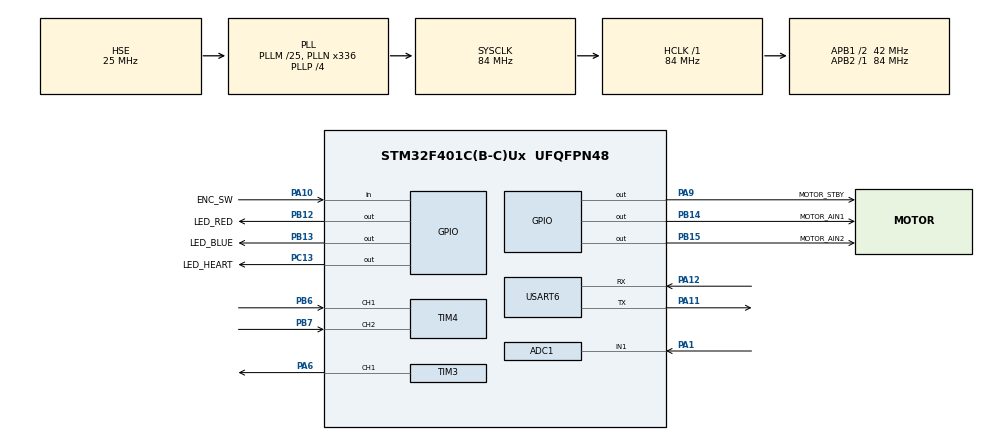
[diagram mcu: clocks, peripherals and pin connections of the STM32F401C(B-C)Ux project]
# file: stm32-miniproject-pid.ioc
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ADC1.Channel-1\#ChannelRegularConversion=ADC_CHANNEL_1
ADC1.NbrOfConversionFlag=1
ADC1.Rank-1\#ChannelRegularConversion=1
ADC1.SamplingTime-1\#ChannelRegularConversion=ADC_SAMPLETIME_84CYCLES
ADC1.master=1
Dma.Request0=USART6_TX
Dma.USART6_TX.0.Direction=DMA_MEMORY_TO_PERIPH
Dma.USART6_TX.0.FIFOMode=DMA_FIFOMODE_DISABLE
Dma.USART6_TX.0.Instance=DMA2_Stream6
Dma.USART6_TX.0.MemDataAlignment=DMA_MDATAALIGN_BYTE
Dma.USART6_TX.0.MemInc=DMA_MINC_ENABLE
Dma.USART6_TX.0.Mode=DMA_NORMAL
Dma.USART6_TX.0.PeriphDataAlignment=DMA_PDATAALIGN_BYTE
Dma.USART6_TX.0.PeriphInc=DMA_PINC_DISABLE
Dma.USART6_TX.0.Priority=DMA_PRIORITY_LOW
FREERTOS.Tasks01=defaultTask,24,128,StartDefaultTask,Default,NULL,Dynamic,NULL,NULL
FREERTOS.configCHECK_FOR_STACK_OVERFLOW=2
FREERTOS.configTOTAL_HEAP_SIZE=4096
FREERTOS.configUSE_NEWLIB_REENTRANT=1
Mcu.Family=STM32F4
Mcu.Name=STM32F401C(B-C)Ux
Mcu.Package=UFQFPN48
NVIC.DMA2_Stream6_IRQn=true\:5\:0\:false\:false\:true\:true\:false\:true\:true
NVIC.PriorityGroup=NVIC_PRIORITYGROUP_4
NVIC.TIM1_UP_TIM10_IRQn=true\:15\:0\:false\:false\:true\:false\:false\:true\:true
NVIC.TimeBase=TIM1_UP_TIM10_IRQn
NVIC.TimeBaseIP=TIM1
PA1.Signal=ADCx_IN1
PA10.GPIO_Label=ENC_SW
PA10.GPIO_PuPd=GPIO_PULLUP
PA10.Signal=GPIO_Input
PA11.Mode=Asynchronous
PA11.Signal=USART6_TX
PA12.Mode=Asynchronous
PA12.Signal=USART6_RX
PA13.Mode=Serial_Wire
PA13.Signal=SYS_JTMS-SWDIO
PA14.Mode=Serial_Wire
PA14.Signal=SYS_JTCK-SWCLK
PA6.Signal=S_TIM3_CH1
PA9.GPIO_Label=MOTOR_STBY
PA9.Signal=GPIO_Output
PB12.GPIO_Label=LED_RED
PB12.Signal=GPIO_Output
PB13.GPIO_Label=LED_BLUE
PB13.Signal=GPIO_Output
PB14.GPIO_Label=MOTOR_AIN1
PB14.PinState=GPIO_PIN_RESET
PB14.Signal=GPIO_Output
PB15.GPIO_Label=MOTOR_AIN2
PB15.PinState=GPIO_PIN_RESET
PB15.Signal=GPIO_Output
PB6.Signal=S_TIM4_CH1
PB7.Signal=S_TIM4_CH2
PC13-ANTI_TAMP.GPIO_Label=LED_HEART
PC13-ANTI_TAMP.PinState=GPIO_PIN_SET
PC13-ANTI_TAMP.Signal=GPIO_Output
PH0\ -\ OSC_IN.Mode=HSE-External-Oscillator
PH0\ -\ OSC_IN.Signal=RCC_OSC_IN
PH1\ -\ OSC_OUT.Mode=HSE-External-Oscillator
PH1\ -\ OSC_OUT.Signal=RCC_OSC_OUT
ProjectManager.HeapSize=0x200
ProjectManager.StackSize=0x400
ProjectManager.TargetToolchain=STM32CubeIDE
RCC.48MHZClocksFreq_Value=84000000
RCC.AHBFreq_Value=84000000
RCC.APB1CLKDivider=RCC_HCLK_DIV2
RCC.APB1Freq_Value=42000000
RCC.APB1TimFreq_Value=84000000
RCC.APB2Freq_Value=84000000
RCC.APB2TimFreq_Value=84000000
RCC.CortexFreq_Value=84000000
RCC.HCLKFreq_Value=84000000
RCC.HSE_VALUE=25000000
RCC.HSI_VALUE=16000000
RCC.LSE_VALUE=32768
RCC.PLLM=25
RCC.PLLN=336
RCC.PLLP=RCC_PLLP_DIV4
RCC.PLLSourceVirtual=RCC_PLLSOURCE_HSE
RCC.SYSCLKFreq_VALUE=84000000
RCC.SYSCLKSource=RCC_SYSCLKSOURCE_PLLCLK
RCC.VCOOutputFreq_Value=336000000
SH.ADCx_IN1.0=ADC1_IN1,IN1
SH.S_TIM3_CH1.0=TIM3_CH1,PWM Generation1 CH1
SH.S_TIM4_CH1.0=TIM4_CH1,Encoder_Interface
SH.S_TIM4_CH2.0=TIM4_CH2,Encoder_Interface
TIM3.AutoReloadPreload=TIM_AUTORELOAD_PRELOAD_ENABLE
TIM3.Channel-PWM\ Generation1\ CH1=TIM_CHANNEL_1
TIM3.Period=4199
TIM4.EncoderMode=TIM_ENCODERMODE_TI12
TIM4.IC1Filter=10
TIM4.IC2Filter=10
USART6.VirtualMode=VM_ASYNC
VP_FREERTOS_VS_CMSIS_V2.Mode=CMSIS_V2
VP_SYS_VS_tim1.Mode=TIM1
VP_TIM3_VS_ClockSourceINT.Mode=Internal
board=custom

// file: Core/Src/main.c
/* USER CODE BEGIN Header */
/**
  ******************************************************************************
  * @file           : main.c
  * @brief          : Main program body
  ******************************************************************************
  * @attention
  *
  * Copyright (c) 2026 STMicroelectronics.
  * All rights reserved.
  *
  * This software is licensed under terms that can be found in the LICENSE file
  * in the root directory of this software component.
  * If no LICENSE file comes with this software, it is provided AS-IS.
  *
  ******************************************************************************
  */
/* USER CODE END Header */
#include "main.h"
#include "cmsis_os.h"

/* USER CODE BEGIN Includes */
#include "app_main.h"
#include <stdio.h>
/* USER CODE END Includes */

ADC_HandleTypeDef hadc1;

TIM_HandleTypeDef htim3;
TIM_HandleTypeDef htim4;

UART_HandleTypeDef huart6;
DMA_HandleTypeDef hdma_usart6_tx;

/* Definitions for defaultTask */
osThreadId_t defaultTaskHandle;
const osThreadAttr_t defaultTask_attributes = {
  .name = "defaultTask",
  .stack_size = 128 * 4,
  .priority = (osPriority_t) osPriorityNormal,
};

void SystemClock_Config(void);
static void MX_GPIO_Init(void);
static void MX_DMA_Init(void);
static void MX_ADC1_Init(void);
static void MX_TIM3_Init(void);
static void MX_TIM4_Init(void);
static void MX_USART6_UART_Init(void);
void StartDefaultTask(void *argument);

/* USER CODE BEGIN 0 */
//int __io_putchar(int ch) {
//    HAL_UART_Transmit(&huart1, (uint8_t *)&ch, 1, 0xFFFF);
//    return ch;
//}
/* USER CODE END 0 */

int main(void)
{

  /* MCU Configuration--------------------------------------------------------*/

  /* Reset of all peripherals, Initializes the Flash interface and the Systick. */
  HAL_Init();

  /* Configure the system clock */
  SystemClock_Config();

  /* Initialize all configured peripherals */
  MX_GPIO_Init();
  MX_DMA_Init();
  MX_ADC1_Init();
  MX_TIM3_Init();
  MX_TIM4_Init();
  MX_USART6_UART_Init();
  /* USER CODE BEGIN 2 */
  app_init();
  /* USER CODE END 2 */

  /* Init scheduler */
  osKernelInitialize();

  /* Create the thread(s) */
  /* creation of defaultTask */
  defaultTaskHandle = osThreadNew(StartDefaultTask, NULL, &defaultTask_attributes);

  /* USER CODE BEGIN RTOS_THREADS */

  // delete generated task from CubeMX
  if (defaultTaskHandle != NULL) {
     osThreadTerminate(defaultTaskHandle);
     defaultTaskHandle = NULL;
  }

  app_start();

  /* USER CODE END RTOS_THREADS */

  /* Start scheduler */
  osKernelStart();

  /* We should never get here as control is now taken by the scheduler */

  /* Infinite loop */
  while (1)
  {

  }
}

void SystemClock_Config(void)
{
  RCC_OscInitTypeDef RCC_OscInitStruct = {0};
  RCC_ClkInitTypeDef RCC_ClkInitStruct = {0};

  /** Configure the main internal regulator output voltage
  */
  __HAL_RCC_PWR_CLK_ENABLE();
  __HAL_PWR_VOLTAGESCALING_CONFIG(PWR_REGULATOR_VOLTAGE_SCALE2);

  /** Initializes the RCC Oscillators according to the specified parameters
  * in the RCC_OscInitTypeDef structure.
  */
  RCC_OscInitStruct.OscillatorType = RCC_OSCILLATORTYPE_HSE;
  RCC_OscInitStruct.HSEState = RCC_HSE_ON;
  RCC_OscInitStruct.PLL.PLLState = RCC_PLL_ON;
  RCC_OscInitStruct.PLL.PLLSource = RCC_PLLSOURCE_HSE;
  RCC_OscInitStruct.PLL.PLLM = 25;
  RCC_OscInitStruct.PLL.PLLN = 336;
  RCC_OscInitStruct.PLL.PLLP = RCC_PLLP_DIV4;
  RCC_OscInitStruct.PLL.PLLQ = 4;
  if (HAL_RCC_OscConfig(&RCC_OscInitStruct) != HAL_OK)
  {
    Error_Handler();
  }

  /** Initializes the CPU, AHB and APB buses clocks
  */
  RCC_ClkInitStruct.ClockType = RCC_CLOCKTYPE_HCLK|RCC_CLOCKTYPE_SYSCLK
                              |RCC_CLOCKTYPE_PCLK1|RCC_CLOCKTYPE_PCLK2;
  RCC_ClkInitStruct.SYSCLKSource = RCC_SYSCLKSOURCE_PLLCLK;
  RCC_ClkInitStruct.AHBCLKDivider = RCC_SYSCLK_DIV1;
  RCC_ClkInitStruct.APB1CLKDivider = RCC_HCLK_DIV2;
  RCC_ClkInitStruct.APB2CLKDivider = RCC_HCLK_DIV1;

  if (HAL_RCC_ClockConfig(&RCC_ClkInitStruct, FLASH_LATENCY_2) != HAL_OK)
  {
    Error_Handler();
  }
}

static void MX_ADC1_Init(void)
{

  ADC_ChannelConfTypeDef sConfig = {0};

  /** Configure the global features of the ADC (Clock, Resolution, Data Alignment and number of conversion)
  */
  hadc1.Instance = ADC1;
  hadc1.Init.ClockPrescaler = ADC_CLOCK_SYNC_PCLK_DIV4;
  hadc1.Init.Resolution = ADC_RESOLUTION_12B;
  hadc1.Init.ScanConvMode = DISABLE;
  hadc1.Init.ContinuousConvMode = DISABLE;
  hadc1.Init.DiscontinuousConvMode = DISABLE;
  hadc1.Init.ExternalTrigConvEdge = ADC_EXTERNALTRIGCONVEDGE_NONE;
  hadc1.Init.ExternalTrigConv = ADC_SOFTWARE_START;
  hadc1.Init.DataAlign = ADC_DATAALIGN_RIGHT;
  hadc1.Init.NbrOfConversion = 1;
  hadc1.Init.DMAContinuousRequests = DISABLE;
  hadc1.Init.EOCSelection = ADC_EOC_SINGLE_CONV;
  if (HAL_ADC_Init(&hadc1) != HAL_OK)
  {
    Error_Handler();
  }

  /** Configure for the selected ADC regular channel its corresponding rank in the sequencer and its sample time.
  */
  sConfig.Channel = ADC_CHANNEL_1;
  sConfig.Rank = 1;
  sConfig.SamplingTime = ADC_SAMPLETIME_84CYCLES;
  if (HAL_ADC_ConfigChannel(&hadc1, &sConfig) != HAL_OK)
  {
    Error_Handler();
  }

}

static void MX_TIM3_Init(void)
{

  TIM_ClockConfigTypeDef sClockSourceConfig = {0};
  TIM_MasterConfigTypeDef sMasterConfig = {0};
  TIM_OC_InitTypeDef sConfigOC = {0};

  htim3.Instance = TIM3;
  htim3.Init.Prescaler = 0;
  htim3.Init.CounterMode = TIM_COUNTERMODE_UP;
  htim3.Init.Period = 4199;
  htim3.Init.ClockDivision = TIM_CLOCKDIVISION_DIV1;
  htim3.Init.AutoReloadPreload = TIM_AUTORELOAD_PRELOAD_ENABLE;
  if (HAL_TIM_Base_Init(&htim3) != HAL_OK)
  {
    Error_Handler();
  }
  sClockSourceConfig.ClockSource = TIM_CLOCKSOURCE_INTERNAL;
  if (HAL_TIM_ConfigClockSource(&htim3, &sClockSourceConfig) != HAL_OK)
  {
    Error_Handler();
  }
  if (HAL_TIM_PWM_Init(&htim3) != HAL_OK)
  {
    Error_Handler();
  }
  sMasterConfig.MasterOutputTrigger = TIM_TRGO_RESET;
  sMasterConfig.MasterSlaveMode = TIM_MASTERSLAVEMODE_DISABLE;
  if (HAL_TIMEx_MasterConfigSynchronization(&htim3, &sMasterConfig) != HAL_OK)
  {
    Error_Handler();
  }
  sConfigOC.OCMode = TIM_OCMODE_PWM1;
  sConfigOC.Pulse = 0;
  sConfigOC.OCPolarity = TIM_OCPOLARITY_HIGH;
  sConfigOC.OCFastMode = TIM_OCFAST_DISABLE;
  if (HAL_TIM_PWM_ConfigChannel(&htim3, &sConfigOC, TIM_CHANNEL_1) != HAL_OK)
  {
    Error_Handler();
  }
  HAL_TIM_MspPostInit(&htim3);

}

static void MX_TIM4_Init(void)
{

  TIM_Encoder_InitTypeDef sConfig = {0};
  TIM_MasterConfigTypeDef sMasterConfig = {0};

  htim4.Instance = TIM4;
  htim4.Init.Prescaler = 0;
  htim4.Init.CounterMode = TIM_COUNTERMODE_UP;
  htim4.Init.Period = 65535;
  htim4.Init.ClockDivision = TIM_CLOCKDIVISION_DIV1;
  htim4.Init.AutoReloadPreload = TIM_AUTORELOAD_PRELOAD_DISABLE;
  sConfig.EncoderMode = TIM_ENCODERMODE_TI12;
  sConfig.IC1Polarity = TIM_ICPOLARITY_RISING;
  sConfig.IC1Selection = TIM_ICSELECTION_DIRECTTI;
  sConfig.IC1Prescaler = TIM_ICPSC_DIV1;
  sConfig.IC1Filter = 10;
  sConfig.IC2Polarity = TIM_ICPOLARITY_RISING;
  sConfig.IC2Selection = TIM_ICSELECTION_DIRECTTI;
  sConfig.IC2Prescaler = TIM_ICPSC_DIV1;
  sConfig.IC2Filter = 10;
  if (HAL_TIM_Encoder_Init(&htim4, &sConfig) != HAL_OK)
  {
    Error_Handler();
  }
  sMasterConfig.MasterOutputTrigger = TIM_TRGO_RESET;
  sMasterConfig.MasterSlaveMode = TIM_MASTERSLAVEMODE_DISABLE;
  if (HAL_TIMEx_MasterConfigSynchronization(&htim4, &sMasterConfig) != HAL_OK)
  {
    Error_Handler();
  }

}

static void MX_USART6_UART_Init(void)
{

  huart6.Instance = USART6;
  huart6.Init.BaudRate = 115200;
  huart6.Init.WordLength = UART_WORDLENGTH_8B;
  huart6.Init.StopBits = UART_STOPBITS_1;
  huart6.Init.Parity = UART_PARITY_NONE;
  huart6.Init.Mode = UART_MODE_TX_RX;
  huart6.Init.HwFlowCtl = UART_HWCONTROL_NONE;
  huart6.Init.OverSampling = UART_OVERSAMPLING_16;
  if (HAL_UART_Init(&huart6) != HAL_OK)
  {
    Error_Handler();
  }

}

static void MX_DMA_Init(void)
{

  /* DMA controller clock enable */
  __HAL_RCC_DMA2_CLK_ENABLE();

  /* DMA interrupt init */
  /* DMA2_Stream6_IRQn interrupt configuration */
  HAL_NVIC_SetPriority(DMA2_Stream6_IRQn, 5, 0);
  HAL_NVIC_EnableIRQ(DMA2_Stream6_IRQn);

}

static void MX_GPIO_Init(void)
{
  GPIO_InitTypeDef GPIO_InitStruct = {0};

  /* GPIO Ports Clock Enable */
  __HAL_RCC_GPIOC_CLK_ENABLE();
  __HAL_RCC_GPIOH_CLK_ENABLE();
  __HAL_RCC_GPIOA_CLK_ENABLE();
  __HAL_RCC_GPIOB_CLK_ENABLE();

  /*Configure GPIO pin Output Level */
  HAL_GPIO_WritePin(LED_HEART_GPIO_Port, LED_HEART_Pin, GPIO_PIN_SET);

  /*Configure GPIO pin Output Level */
  HAL_GPIO_WritePin(GPIOB, LED_RED_Pin|LED_BLUE_Pin|MOTOR_AIN1_Pin|MOTOR_AIN2_Pin, GPIO_PIN_RESET);

  /*Configure GPIO pin Output Level */
  HAL_GPIO_WritePin(MOTOR_STBY_GPIO_Port, MOTOR_STBY_Pin, GPIO_PIN_RESET);

  /*Configure GPIO pin : LED_HEART_Pin */
  GPIO_InitStruct.Pin = LED_HEART_Pin;
  GPIO_InitStruct.Mode = GPIO_MODE_OUTPUT_PP;
  GPIO_InitStruct.Pull = GPIO_NOPULL;
  GPIO_InitStruct.Speed = GPIO_SPEED_FREQ_LOW;
  HAL_GPIO_Init(LED_HEART_GPIO_Port, &GPIO_InitStruct);

  /*Configure GPIO pins : LED_RED_Pin LED_BLUE_Pin MOTOR_AIN1_Pin MOTOR_AIN2_Pin */
  GPIO_InitStruct.Pin = LED_RED_Pin|LED_BLUE_Pin|MOTOR_AIN1_Pin|MOTOR_AIN2_Pin;
  GPIO_InitStruct.Mode = GPIO_MODE_OUTPUT_PP;
  GPIO_InitStruct.Pull = GPIO_NOPULL;
  GPIO_InitStruct.Speed = GPIO_SPEED_FREQ_LOW;
  HAL_GPIO_Init(GPIOB, &GPIO_InitStruct);

  /*Configure GPIO pin : MOTOR_STBY_Pin */
  GPIO_InitStruct.Pin = MOTOR_STBY_Pin;
  GPIO_InitStruct.Mode = GPIO_MODE_OUTPUT_PP;
  GPIO_InitStruct.Pull = GPIO_NOPULL;
  GPIO_InitStruct.Speed = GPIO_SPEED_FREQ_LOW;
  HAL_GPIO_Init(MOTOR_STBY_GPIO_Port, &GPIO_InitStruct);

  /*Configure GPIO pin : ENC_SW_Pin */
  GPIO_InitStruct.Pin = ENC_SW_Pin;
  GPIO_InitStruct.Mode = GPIO_MODE_INPUT;
  GPIO_InitStruct.Pull = GPIO_PULLUP;
  HAL_GPIO_Init(ENC_SW_GPIO_Port, &GPIO_InitStruct);

}

void StartDefaultTask(void *argument)
{
}

void HAL_TIM_PeriodElapsedCallback(TIM_HandleTypeDef *htim)
{
  if (htim->Instance == TIM1)
  {
    HAL_IncTick();
  }
}

void Error_Handler(void)
{
  __disable_irq();
  while (1)
  {
  }
}
